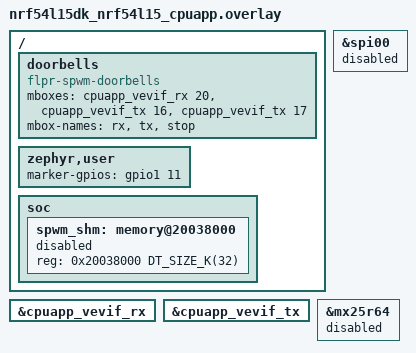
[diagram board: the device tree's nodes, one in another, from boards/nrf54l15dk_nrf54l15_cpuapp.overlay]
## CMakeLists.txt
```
#
# Copyright (c) 2026 Nordic Semiconductor ASA
#
# SPDX-License-Identifier: Apache-2.0
#

cmake_minimum_required(VERSION 3.20.0)

# The FLPR image in remote/ only builds through sysbuild.cmake. An app-only build still links,
# then boots whatever is in the FLPR partition.
if(NOT SYSBUILD)
  message(FATAL_ERROR "flpr_spwm needs sysbuild: west build --sysbuild ...")
endif()

# Reserves FLPR code/data SRAM and makes the app core boot the FLPR image.
list(APPEND SNIPPET nordic-flpr)

find_package(Zephyr REQUIRED HINTS $ENV{ZEPHYR_BASE})
project(flpr_spwm)

target_sources(app PRIVATE src/main.c src/pattern.c src/spwm.c)
target_include_directories(app PRIVATE include)
```

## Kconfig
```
# Copyright (c) 2026 Nordic Semiconductor ASA
#
# SPDX-License-Identifier: Apache-2.0

config FLPR_SPWM_BLE
	bool "Advertise over BLE while the FLPR streams"
	depends on BT
	help
	  Non-connectable advertising at a 20 ms interval, to load the app core
	  and RAM while the bench cases run (B5, O3). overlay-ble.conf sets it.

source "Kconfig.zephyr"
```

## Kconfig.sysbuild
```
# Copyright (c) 2026 Nordic Semiconductor ASA
#
# SPDX-License-Identifier: Apache-2.0

source "share/sysbuild/Kconfig"

config REMOTE_BOARD
	string "FLPR board target"
	default "nrf54l15dk/nrf54l15/cpuflpr" if $(BOARD) = "nrf54l15dk"
	default "nrf54lm20dk/nrf54lm20a/cpuflpr" if "$(BOARD)/$(BOARD_QUALIFIERS)" = "nrf54lm20dk/nrf54lm20a/cpuapp"
```

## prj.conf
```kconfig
CONFIG_MBOX=y
CONFIG_LOG=y
# sinf() in hardware. Load marker: 358 -> 204 us for a 10-step compile at 64 MHz.
CONFIG_FPU=y
```

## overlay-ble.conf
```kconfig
# B5: BLE advertising on the app core while the FLPR streams
CONFIG_BT=y
CONFIG_BT_DEVICE_NAME="flpr_spwm"
CONFIG_FLPR_SPWM_BLE=y
```

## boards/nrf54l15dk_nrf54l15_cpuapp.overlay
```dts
/*
 * Copyright (c) 2026 Nordic Semiconductor ASA
 *
 * SPDX-License-Identifier: Apache-2.0
 */

/* VEVIF doorbells. The app rings FLPR task 16 (START) and 17 (STOP), and the FLPR answers on
 * event 20 (DONE), the only FLPR->app event Zephyr's vevif event-rx accepts on 54L.
 */
/ {
	doorbells {
		compatible = "flpr-spwm-doorbells";
		mboxes = <&cpuapp_vevif_rx 20>, <&cpuapp_vevif_tx 16>, <&cpuapp_vevif_tx 17>;
		mbox-names = "rx", "tx", "stop";
	};
};

/* nordic-flpr only enables the tx side */
&cpuapp_vevif_rx {
	status = "okay";
};

&cpuapp_vevif_tx {
	status = "okay";
};

/* Load marker, high while the app compiles and loads a pattern. P1.11 is only on
 * the expansion-header gpio-map, no board device claims it.
 */
/ {
	zephyr,user {
		marker-gpios = <&gpio1 11 GPIO_ACTIVE_HIGH>;
	};
};

/* P2.01/P2.02 are the only VIO0/VIO1 pins and the DK routes them to the external flash.
 * The FLPR takes them, so the flash has to go. Board Configurator moves them to the P2 header.
 */
&spi00 {
	status = "disabled";
};

&mx25r64 {
	status = "disabled";
};

/* Control block + pattern buffers, top 32 KB of the nordic-flpr region. The FLPR image is
 * linked into the bottom 64 KB (remote overlay). The snippet's reserved node still covers
 * all 96 KB, so the app never links anything here.
 * nordic_vpr_launcher copies all 96 KB from RRAM at boot, so the app fills it after that.
 */
/ {
	soc {
		spwm_shm: memory@20038000 {
			reg = <0x20038000 DT_SIZE_K(32)>;
			status = "reserved";
		};
	};
};
```

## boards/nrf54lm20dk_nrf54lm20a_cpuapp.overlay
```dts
/*
 * Copyright (c) 2026 Nordic Semiconductor ASA
 *
 * SPDX-License-Identifier: Apache-2.0
 */

/* Same doorbells as nRF54L15, see nrf54l15dk_nrf54l15_cpuapp.overlay */
/ {
	doorbells {
		compatible = "flpr-spwm-doorbells";
		mboxes = <&cpuapp_vevif_rx 20>, <&cpuapp_vevif_tx 16>, <&cpuapp_vevif_tx 17>;
		mbox-names = "rx", "tx", "stop";
	};
};

&cpuapp_vevif_rx {
	status = "okay";
};

&cpuapp_vevif_tx {
	status = "okay";
};

/* Load marker, high while the app compiles and loads a pattern. P1.03 is only on
 * the expansion-header gpio-map, no board device claims it.
 */
/ {
	zephyr,user {
		marker-gpios = <&gpio1 3 GPIO_ACTIVE_HIGH>;
	};
};

/* P2.01/P2.02 are the only VIO0/VIO1 pins and the DK routes them to the external flash.
 * The FLPR takes them, so the flash has to go. Board Configurator moves them to the P2 header.
 */
&spi00 {
	status = "disabled";
};

&mx25r64 {
	status = "disabled";
};

/* Control block + pattern buffers, top 32 KB of the nordic-flpr region. The FLPR image is
 * linked into the bottom 64 KB (remote overlay). The snippet's reserved node still covers
 * all 96 KB, so the app never links anything here.
 * nordic_vpr_launcher copies all 96 KB from RRAM at boot, so the app fills it after that.
 */
/ {
	soc {
		spwm_shm: memory@20077c00 {
			reg = <0x20077c00 DT_SIZE_K(32)>;
			status = "reserved";
		};
	};
};
```

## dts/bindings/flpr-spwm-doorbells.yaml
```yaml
# Copyright (c) 2026 Nordic Semiconductor ASA
#
# SPDX-License-Identifier: Apache-2.0

description: VEVIF doorbells between the app core and the FLPR

compatible: "flpr-spwm-doorbells"

include: base.yaml

properties:
  mboxes:
    required: true

  mbox-names:
    required: true
```

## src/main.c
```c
/*
 * Copyright (c) 2026 Nordic Semiconductor ASA
 *
 * SPDX-License-Identifier: Apache-2.0
 */

/** @file
 *  @brief App core side of flpr_spwm.
 *
 *  Bench sequence, repeated: compile a pattern with the load marker high, START it, wait
 *  for DONE, log the result. One case per bench milestone, see cases[].
 */

#include <zephyr/kernel.h>
#include <zephyr/logging/log.h>
#include <zephyr/bluetooth/bluetooth.h>

#include "pattern.h"
#include "spwm.h"
#include "spwm_ipc.h"

LOG_MODULE_REGISTER(flpr_spwm, LOG_LEVEL_INF);

#define GAP_MS 200
#define MAX_STEPS 4096
#define BUF_OFF SPWM_SHM_BUF_OFF
#define REF_HZ 200000
#define RATIO 10 /* carrier = 10 * ref, 2 MHz at 200 kHz */

/* loop_cnt that plays about 20 ms, whatever the buffer length */
#define LOOPS_20MS UINT32_MAX

enum shape {
	SHAPE_ALT, /* A, B, A, B at the minimum dead time, worst case for A/B changes */
	SHAPE_SINE,
	SHAPE_RETUNE,   /* sine at f_ref, then retune_hz from a second buffer, then STOP */
	SHAPE_MINPULSE, /* A only, on_ticks 1..8 in 32-tick periods */
};

struct bench_case {
	const char *name;
	enum shape shape;
	uint16_t cnttop;
	uint16_t dead_ticks;
	uint32_t loop_cnt; /* 0: run until spwm_stop() after stop_after_us */
	uint32_t stop_after_us;
	uint32_t f_ref;     /* 0: REF_HZ */
	uint32_t max_words; /* planner buffer cap, 0: one ref cycle */
	uint32_t retune_hz;
};

static const struct bench_case cases[] = {
	{"b2_alt_64M", SHAPE_ALT, 1, 2, 1000},
	{"b3_sine_64M", SHAPE_SINE, 1, 2, 2000},
	{"b3_sine_128M", SHAPE_SINE, 0, 4, 2000},
	{"b4_n100_64M", SHAPE_SINE, 1, 2, 100},
	{"b4_stop_64M", SHAPE_SINE, 1, 2, 0, 2000},
	/* STOP right after START, before the FLPR picks it up: must still stop after one pass */
	{"b4_stop_early_64M", SHAPE_SINE, 1, 2, 0, 0},
	{"b6_retune_64M", SHAPE_RETUNE, 1, 2, 0, 1000, 0, 0, 188235},
	/* Limits at 128 MHz: 1-tick dead time, pulse floor, fine frequency steps */
	{"b2_alt_128M_d1", SHAPE_ALT, 0, 1, 2000},
	{"b8_minpulse_128M", SHAPE_MINPULSE, 0, 4, 1000},
	{"b7_f200000", SHAPE_SINE, 0, 1, LOOPS_20MS, 0, 200000, SPWM_SHM_BUF_MAX_WORDS},
	{"b7_f187654", SHAPE_SINE, 0, 1, LOOPS_20MS, 0, 187654, SPWM_SHM_BUF_MAX_WORDS},
	{"b7_f187655", SHAPE_SINE, 0, 1, LOOPS_20MS, 0, 187655, SPWM_SHM_BUF_MAX_WORDS},
	{"b7_f187664", SHAPE_SINE, 0, 1, LOOPS_20MS, 0, 187664, SPWM_SHM_BUF_MAX_WORDS},
};

static struct spwm_step steps[MAX_STEPS];
static struct spwm_sine_plan plan;

#if defined(CONFIG_FLPR_SPWM_BLE)
static const struct bt_data ad[] = {
	BT_DATA_BYTES(BT_DATA_FLAGS, BT_LE_AD_NO_BREDR),
	BT_DATA(BT_DATA_NAME_COMPLETE, CONFIG_BT_DEVICE_NAME, sizeof(CONFIG_BT_DEVICE_NAME) - 1),
};

/* 20 ms, the shortest advertising interval (BT Core v5.x, Vol 6, Part B, 4.4.2.2.1) */
#define ADV_INT_20MS 0x20

static int ble_start(void)
{
	const struct bt_le_adv_param param =
		BT_LE_ADV_PARAM_INIT(BT_LE_ADV_OPT_USE_IDENTITY, ADV_INT_20MS, ADV_INT_20MS, NULL);
	int err;

	err = bt_enable(NULL);
	if (err) {
		LOG_ERR("bt_enable failed (err %d)", err);
		return err;
	}

	err = bt_le_adv_start(&param, ad, ARRAY_SIZE(ad), NULL, 0);
	if (err) {
		LOG_ERR("bt_le_adv_start failed (err %d)", err);
		return err;
	}

	LOG_INF("advertising as %s every 20 ms", CONFIG_BT_DEVICE_NAME);

	return 0;
}
#else
static int ble_start(void)
{
	return -ENOTSUP;
}
#endif /* CONFIG_FLPR_SPWM_BLE */

static uint32_t tick_hz_of(const struct bench_case *c)
{
	return 128000000U / (c->cnttop + 1U);
}

/* Plans and compiles a sine into spwm_shm at off. max_words 0 = one ref cycle, as before. */
static int build_sine(const struct bench_case *c, uint32_t f_ref, uint32_t max_words,
		      uint32_t off)
{
	uint32_t room = SPWM_SHM_BUF_MAX_WORDS - (off - BUF_OFF) / sizeof(uint32_t);
	uint32_t tick_hz = tick_hz_of(c);
	uint32_t max_ticks;
	int n;
	int err;

	if (max_words == 0) {
		/* One ref cycle, rounded to whole words */
		max_ticks = ROUND_UP(tick_hz / f_ref, SPWM_TICKS_PER_WORD);
	} else {
		max_ticks = MIN(max_words, room) * SPWM_TICKS_PER_WORD;
	}

	err = spwm_sine_plan(f_ref, RATIO, tick_hz, max_ticks, MAX_STEPS, &plan);
	if (err) {
		return err;
	}

	n = spwm_sine_build(&plan, 100, c->dead_ticks, steps, MAX_STEPS);
	if (n < 0) {
		return n;
	}

	return spwm_compile(steps, n, c->dead_ticks, (uint32_t *)SPWM_BUF(off), room);
}

static int build(const struct bench_case *c)
{
	size_t n;

	switch (c->shape) {
	case SHAPE_ALT:
		/* period 16, pulse fills it but for dead_ticks each side */
		n = 4;
		for (size_t k = 0; k < n; k++) {
			steps[k] = (struct spwm_step){
				.leg = (k & 1) ? SPWM_LEG_B : SPWM_LEG_A,
				.dead_ticks = c->dead_ticks,
				.on_ticks = 16 - 2 * c->dead_ticks,
				.period_ticks = 16,
			};
		}
		break;
	case SHAPE_MINPULSE:
		n = 8;
		for (size_t k = 0; k < n; k++) {
			steps[k] = (struct spwm_step){
				.leg = SPWM_LEG_A,
				.dead_ticks = c->dead_ticks,
				.on_ticks = k + 1,
				.period_ticks = 32,
			};
		}
		break;
	default:
		return build_sine(c, c->f_ref ? c->f_ref : REF_HZ, c->max_words, BUF_OFF);
	}

	return spwm_compile(steps, n, c->dead_ticks, (uint32_t *)SPWM_BUF(BUF_OFF),
			    SPWM_SHM_BUF_MAX_WORDS);
}

static int run_case(const struct bench_case *c)
{
	uint32_t t_start, t_done;
	uint32_t retune_off = 0;
	int retune_words = 0;
	int words;
	int err;

	spwm_marker(true);
	words = build(c);
	if (c->shape == SHAPE_RETUNE && words > 0) {
		retune_off = BUF_OFF + words * sizeof(uint32_t);
		retune_words = build_sine(c, c->retune_hz, 85, retune_off);
	}
	spwm_marker(false);
	if (retune_words < 0) {
		LOG_ERR("%s: retune compile failed (err %d)", c->name, retune_words);
		return retune_words;
	}
	if (words < 0) {
		LOG_ERR("%s: compile failed (err %d)", c->name, words);
		return words;
	}

	uint32_t loop_cnt = c->loop_cnt;

	if (loop_cnt == LOOPS_20MS) {
		/* words * 16 ticks per pass */
		loop_cnt = MAX(1U, (uint32_t)((uint64_t)tick_hz_of(c) / 50U /
					      ((uint64_t)words * SPWM_TICKS_PER_WORD)));
	}

	if (c->shape == SHAPE_SINE && c->max_words) {
		LOG_INF("%s: plan M %u L %u ticks, f %u.%03u Hz", c->name, plan.cycles, plan.ticks,
			(uint32_t)(plan.f_mhz / 1000U), (uint32_t)(plan.f_mhz % 1000U));
	}

	t_start = k_cycle_get_32();
	err = spwm_start(BUF_OFF, words, c->cnttop, loop_cnt);
	if (err) {
		LOG_ERR("%s: spwm_start failed (err %d)", c->name, err);
		return err;
	}

	if (c->shape == SHAPE_RETUNE) {
		k_busy_wait(c->stop_after_us);
		err = spwm_retune(retune_off, retune_words);
		if (err) {
			LOG_ERR("%s: spwm_retune failed (err %d)", c->name, err);
			return err;
		}
	}

	if (loop_cnt == 0) {
		k_busy_wait(c->stop_after_us);
		err = spwm_stop();
		if (err) {
			LOG_ERR("%s: spwm_stop failed (err %d)", c->name, err);
			return err;
		}
	}

	err = spwm_wait_done(K_SECONDS(1), &t_done);
	if (err) {
		LOG_ERR("%s: no DONE, state %u", c->name, SPWM_CTRL->state);
		return err;
	}

	LOG_INF("%s: %d words, cnttop %u, loop_cnt %u, loops_done %u, state %u, "
		"START->DONE %u us",
		c->name, words, c->cnttop, loop_cnt, SPWM_CTRL->loops_done, SPWM_CTRL->state,
		k_cyc_to_us_floor32(t_done - t_start));

	return 0;
}

int main(void)
{
	int err;

	err = spwm_init();
	if (err) {
		return err;
	}

	if (IS_ENABLED(CONFIG_FLPR_SPWM_BLE)) {
		err = ble_start();
		if (err) {
			return err;
		}
	}

	LOG_INF("flpr_spwm on %s, spwm_shm 0x%08x, %u buffer words", CONFIG_BOARD_TARGET,
		SPWM_SHM_ADDR, SPWM_SHM_BUF_MAX_WORDS);

	while (1) {
		for (size_t i = 0; i < ARRAY_SIZE(cases); i++) {
			(void)run_case(&cases[i]);
			k_msleep(GAP_MS);
		}
	}

	return 0;
}
```

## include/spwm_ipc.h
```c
/*
 * Copyright (c) 2026 Nordic Semiconductor ASA
 *
 * SPDX-License-Identifier: Apache-2.0
 */

/** @file
 *  @brief Control block shared by the app core and the FLPR.
 *
 *  Lives at the start of the spwm_shm DT region, which both images carve out of the
 *  top 32 KB of the nordic-flpr SRAM. Pattern buffers follow it in the same region.
 *  All offsets are bytes from the region base, so neither side needs the other's pointers.
 */

#ifndef SPWM_IPC_H_
#define SPWM_IPC_H_

#include <stdint.h>
#include <zephyr/devicetree.h>

#define SPWM_IPC_VERSION 2

#define SPWM_SHM_ADDR DT_REG_ADDR(DT_NODELABEL(spwm_shm))
#define SPWM_SHM_SIZE DT_REG_SIZE(DT_NODELABEL(spwm_shm))

/* Pattern buffers start here, 64 B keeps the control block on its own */
#define SPWM_SHM_BUF_OFF 64U
#define SPWM_SHM_BUF_MAX_WORDS ((SPWM_SHM_SIZE - SPWM_SHM_BUF_OFF) / sizeof(uint32_t))

/* One 32-bit OUTB word holds 16 two-bit frames (FRAMEWIDTH = 2, SHIFTCNTB = 15) */
#define SPWM_TICKS_PER_WORD 16U

enum spwm_state {
	SPWM_STATE_IDLE = 0,
	SPWM_STATE_ARMED,
	SPWM_STATE_RUNNING,
	SPWM_STATE_DONE,
	SPWM_STATE_ERROR,
};

enum spwm_err {
	SPWM_ERR_NONE = 0,
	SPWM_ERR_VERSION,
	SPWM_ERR_BUF,
};

struct spwm_ctrl {
	uint32_t version;        /* app: SPWM_IPC_VERSION, FLPR checks it at START */
	uint32_t state;          /* FLPR: enum spwm_state */
	uint32_t err;            /* FLPR: enum spwm_err when state is ERROR */
	uint32_t buf_off;        /* app: buffer to play */
	uint32_t buf_words;      /* app */
	uint32_t next_buf_off;   /* app: retune, taken at the next wrap with pending. 0 = none */
	uint32_t next_buf_words; /* app */
	uint32_t loop_cnt;       /* app: buffer plays per START. 0 = until STOP */
	uint32_t cnttop;         /* app: VTIM CNT0 top, tick = 128 MHz / (cnttop + 1) (O2) */
	uint32_t stop_req;       /* app: taken at the next wrap with pending */
	uint32_t loops_done;     /* FLPR: written at the end, and at a wrap that sees pending */
	uint32_t pending;        /* app: set last, after stop_req or next_buf_*. FLPR clears it */
};

BUILD_ASSERT(sizeof(struct spwm_ctrl) <= SPWM_SHM_BUF_OFF, "control block overlaps buffers");

#define SPWM_CTRL ((volatile struct spwm_ctrl *)SPWM_SHM_ADDR)
#define SPWM_BUF(off) ((volatile uint32_t *)(SPWM_SHM_ADDR + (off)))

#endif /* SPWM_IPC_H_ */
```

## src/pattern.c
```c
/*
 * Copyright (c) 2026 Nordic Semiconductor ASA
 *
 * SPDX-License-Identifier: Apache-2.0
 */

#include <errno.h>
#include <math.h>
#include <string.h>

#include "pattern.h"

#define TICKS_PER_WORD 16 /* FRAMEWIDTH 2 in a 32-bit OUTB word */
#define FRAME_A 0x1U      /* VIO0 */
#define FRAME_B 0x2U      /* VIO1 */

#define PI_F 3.14159265f

static uint32_t frame_get(const uint32_t *buf, size_t tick)
{
	return (buf[tick / TICKS_PER_WORD] >> (2 * (tick % TICKS_PER_WORD))) & 0x3U;
}

int spwm_sine_plan(uint32_t f_ref, uint16_t carrier_ratio, uint32_t tick_hz, uint32_t max_ticks,
		   size_t max_steps, struct spwm_sine_plan *plan)
{
	uint64_t best_err = UINT64_MAX;
	uint32_t best_l = 0;
	uint32_t best_m = 0;

	if (f_ref == 0 || carrier_ratio == 0 || tick_hz == 0) {
		return -EINVAL;
	}

	for (uint32_t l = TICKS_PER_WORD; l <= max_ticks; l += TICKS_PER_WORD) {
		uint32_t m = (uint32_t)(((uint64_t)f_ref * l + tick_hz / 2) / tick_hz);

		if (m == 0 || (uint64_t)m * carrier_ratio > max_steps) {
			continue;
		}

		/* |tick_hz * M / L - f_ref| * L, compared across L by cross-multiplying */
		uint64_t a = (uint64_t)tick_hz * m;
		uint64_t b = (uint64_t)f_ref * l;
		uint64_t err = a > b ? a - b : b - a;

		if (best_l == 0 || err * best_l < best_err * l) {
			best_err = err;
			best_l = l;
			best_m = m;
			if (err == 0) {
				break;
			}
		}
	}

	if (best_l == 0) {
		return -EINVAL;
	}

	plan->tick_hz = tick_hz;
	plan->carrier_ratio = carrier_ratio;
	plan->cycles = best_m;
	plan->ticks = best_l;
	plan->f_mhz = ((uint64_t)tick_hz * 1000U * best_m + best_l / 2) / best_l;

	return 0;
}

int spwm_sine_build(const struct spwm_sine_plan *plan, uint8_t depth_pct, uint16_t dead_ticks,
		    struct spwm_step *steps, size_t max_steps)
{
	uint32_t n = plan->cycles * plan->carrier_ratio;
	uint32_t l = plan->ticks;

	if (depth_pct > 100) {
		return -EINVAL;
	}
	if (n > max_steps) {
		return -ENOMEM;
	}

	for (uint32_t k = 0; k < n; k++) {
		/* Carrier k spans [s, e), edges on the nearest tick below k * L / N */
		uint32_t s = (uint32_t)((uint64_t)k * l / n);
		uint32_t e = (uint32_t)((uint64_t)(k + 1) * l / n);
		uint32_t period = e - s;

		if (period > UINT16_MAX || period <= 2U * dead_ticks) {
			return -EINVAL;
		}

		/* Phase at the carrier center (s + e) / 2, reduced mod 2L in integers first */
		uint64_t num = ((uint64_t)plan->cycles * (s + e)) % (2ULL * l);
		float v = sinf(2.0f * PI_F * (float)num / (float)(2U * l));
		uint32_t on = (uint32_t)lroundf(fabsf(v) * depth_pct * (period - 2U * dead_ticks) /
						100.0f);

		steps[k].period_ticks = period;
		steps[k].dead_ticks = dead_ticks;
		steps[k].on_ticks = on;
		steps[k].leg = (on == 0) ? SPWM_LEG_NONE : (v > 0.0f ? SPWM_LEG_A : SPWM_LEG_B);
	}

	return (int)n;
}

int spwm_validate(const uint32_t *buf, size_t words, uint16_t min_dead_ticks)
{
	size_t ticks = words * TICKS_PER_WORD;
	uint32_t last = 0;
	uint32_t low_run = 0;

	/* Two passes, so the A/B change across the wrap is checked with real history */
	for (size_t i = 0; i < 2 * ticks; i++) {
		uint32_t f = frame_get(buf, i % ticks);

		if (f == (FRAME_A | FRAME_B)) {
			return -EINVAL;
		}

		if (f == 0) {
			low_run++;
			continue;
		}

		if (last != 0 && last != f && low_run < min_dead_ticks) {
			return -EINVAL;
		}

		last = f;
		low_run = 0;
	}

	return 0;
}

int spwm_compile(const struct spwm_step *steps, size_t n, uint16_t min_dead_ticks,
		 uint32_t *buf, size_t max_words)
{
	size_t ticks = 0;

	for (size_t k = 0; k < n; k++) {
		const struct spwm_step *s = &steps[k];

		if (s->leg > SPWM_LEG_B || s->period_ticks == 0 || s->dead_ticks < min_dead_ticks ||
		    2U * s->dead_ticks + s->on_ticks > s->period_ticks) {
			return -EINVAL;
		}
		ticks += s->period_ticks;
	}

	size_t words = (ticks + TICKS_PER_WORD - 1) / TICKS_PER_WORD;

	if (words == 0 || words > max_words) {
		return -ENOMEM;
	}

	memset(buf, 0, words * sizeof(uint32_t));

	size_t t = 0;

	for (size_t k = 0; k < n; k++) {
		const struct spwm_step *s = &steps[k];
		uint32_t frame = (s->leg == SPWM_LEG_A) ? FRAME_A : FRAME_B;
		/* Centered pulse, odd leftover tick goes after it */
		size_t start = t + (s->period_ticks - s->on_ticks) / 2;

		if (s->leg != SPWM_LEG_NONE) {
			for (size_t i = start; i < start + s->on_ticks; i++) {
				buf[i / TICKS_PER_WORD] |= frame << (2 * (i % TICKS_PER_WORD));
			}
		}
		t += s->period_ticks;
	}

	if (spwm_validate(buf, words, min_dead_ticks)) {
		return -EINVAL;
	}

	return (int)words;
}
```

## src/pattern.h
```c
/*
 * Copyright (c) 2026 Nordic Semiconductor ASA
 *
 * SPDX-License-Identifier: Apache-2.0
 */

/** @file
 *  @brief Bit-pattern compiler for the FLPR streamer.
 *
 *  A step is one carrier period, the analogue of one PWM SEQ value. Steps compile to
 *  2-bit frames, 16 per 32-bit word, LSB first, frame bits [1:0] = {leg B, leg A}.
 */

#ifndef SPWM_PATTERN_H_
#define SPWM_PATTERN_H_

#include <stddef.h>
#include <stdint.h>

enum spwm_leg {
	SPWM_LEG_NONE = 0,
	SPWM_LEG_A,
	SPWM_LEG_B,
};

struct spwm_step {
	uint8_t leg;           /* enum spwm_leg */
	uint16_t dead_ticks;   /* minimum low time before and after the pulse */
	uint16_t on_ticks;     /* pulse width, centered in the period */
	uint16_t period_ticks;
};

/** @brief Buffer layout for a sine at the closest reachable f_ref. */
struct spwm_sine_plan {
	uint32_t tick_hz;
	uint16_t carrier_ratio; /* carrier periods per ref period */
	uint32_t cycles;        /* M, ref cycles in one buffer */
	uint32_t ticks;         /* L, buffer length, a multiple of 16 */
	uint64_t f_mhz;         /* reached f_ref in mHz, tick_hz * M / L */
};

/**
 * @brief Pick the buffer that gets closest to f_ref.
 *
 * f_ref = tick_hz * M / L, L a multiple of 16 ticks. Searches every L up to max_ticks, so a
 * longer buffer gives a finer f_ref and a slower retune (one pass is L ticks). Carrier edges
 * land on the nearest tick, so carrier periods differ by at most one tick inside a buffer.
 *
 * @param f_ref         target, Hz
 * @param carrier_ratio carrier = carrier_ratio * f_ref
 * @param tick_hz       128 MHz / (cnttop + 1)
 * @param max_ticks     longest buffer allowed
 * @param max_steps     step array size, M * carrier_ratio must fit
 * @param plan          output
 *
 * @retval -EINVAL if nothing fits
 */
int spwm_sine_plan(uint32_t f_ref, uint16_t carrier_ratio, uint32_t tick_hz, uint32_t max_ticks,
		   size_t max_steps, struct spwm_sine_plan *plan);

/**
 * @brief Fill steps for a plan, natural-sampled at each carrier's center.
 *
 * Sign picks the leg, |sin| * depth scales the pulse between 0 and period - 2 * dead.
 *
 * @return steps written (M * carrier_ratio), or -EINVAL if a carrier can't hold the dead
 *         time, -ENOMEM if max_steps is too small
 */
int spwm_sine_build(const struct spwm_sine_plan *plan, uint8_t depth_pct, uint16_t dead_ticks,
		    struct spwm_step *steps, size_t max_steps);

/**
 * @brief Pack steps into OUTB words, then validate the words.
 *
 * Pads with low frames to a 16-tick multiple.
 *
 * @param steps          input
 * @param n              step count
 * @param min_dead_ticks dead time every step and every A/B change must honour
 * @param buf            output words
 * @param max_words      buf size
 *
 * @return words written, or -EINVAL on a bad step or failed validation, -ENOMEM if it
 *         doesn't fit
 */
int spwm_compile(const struct spwm_step *steps, size_t n, uint16_t min_dead_ticks,
		 uint32_t *buf, size_t max_words);

/**
 * @brief Check packed words as the FLPR will play them, looping.
 *
 * @retval 0 if no frame has A and B high, and every A->B or B->A change has at least
 *         min_dead_ticks low frames between, including across the buffer wrap
 * @retval -EINVAL otherwise
 */
int spwm_validate(const uint32_t *buf, size_t words, uint16_t min_dead_ticks);

#endif /* SPWM_PATTERN_H_ */
```

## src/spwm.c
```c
/*
 * Copyright (c) 2026 Nordic Semiconductor ASA
 *
 * SPDX-License-Identifier: Apache-2.0
 */

#include <zephyr/kernel.h>
#include <zephyr/drivers/mbox.h>
#include <zephyr/drivers/gpio.h>
#include <zephyr/drivers/clock_control/nrf_clock_control.h>
#include <zephyr/logging/log.h>
#include <soc.h>
#include <hal/nrf_gpio.h>

#include "spwm.h"
#include "spwm_ipc.h"

LOG_MODULE_REGISTER(spwm, LOG_LEVEL_INF);

#define MARKER_PIN NRF_DT_GPIOS_TO_PSEL(DT_PATH(zephyr_user), marker_gpios)

static const struct gpio_dt_spec marker = GPIO_DT_SPEC_GET(DT_PATH(zephyr_user), marker_gpios);

static const struct mbox_dt_spec rx = MBOX_DT_SPEC_GET(DT_PATH(doorbells), rx);
static const struct mbox_dt_spec tx = MBOX_DT_SPEC_GET(DT_PATH(doorbells), tx);
static const struct mbox_dt_spec stop = MBOX_DT_SPEC_GET(DT_PATH(doorbells), stop);

static K_SEM_DEFINE(done_sem, 0, 1);
static volatile uint32_t done_cyc_isr;

void spwm_marker(bool on)
{
	/* Straight to the port, gpio_pin_set_dt() adds a few hundred ns of API on the marker */
	if (on) {
		nrf_gpio_pin_set(MARKER_PIN);
	} else {
		nrf_gpio_pin_clear(MARKER_PIN);
	}
}

/* VPR00 IRQ 76. The marker pulse puts DONE on the same Logic channel as the load marker. */
static void done_cb(const struct device *dev, mbox_channel_id_t channel_id, void *user_data,
		    struct mbox_msg *data)
{
	nrf_gpio_pin_set(MARKER_PIN);
	nrf_gpio_pin_clear(MARKER_PIN);
	/* After the pulse: a GRTC read took 0.9-30 us here on the bench */
	done_cyc_isr = k_cycle_get_32();
	k_sem_give(&done_sem);
}

static int hfxo_start(void)
{
	struct onoff_manager *mgr = z_nrf_clock_control_get_onoff(CLOCK_CONTROL_NRF_SUBSYS_HF);
	struct onoff_client cli;
	int res;
	int err;

	sys_notify_init_spinwait(&cli.notify);
	err = onoff_request(mgr, &cli);
	if (err < 0) {
		return err;
	}

	do {
		err = sys_notify_fetch_result(&cli.notify, &res);
	} while (err == -EAGAIN);

	return err ? err : res;
}

int spwm_init(void)
{
	int err;

	/* HFINT alone put the tick +587 to +1275 ppm off, HFXO +8 ppm (B1) */
	err = hfxo_start();
	if (err) {
		LOG_ERR("HFXO start failed (err %d)", err);
		return err;
	}

	err = gpio_pin_configure_dt(&marker, GPIO_OUTPUT_INACTIVE);
	if (err) {
		LOG_ERR("marker configure failed (err %d)", err);
		return err;
	}

	err = mbox_register_callback_dt(&rx, done_cb, NULL);
	if (err) {
		LOG_ERR("mbox_register_callback_dt failed (err %d)", err);
		return err;
	}

	err = mbox_set_enabled_dt(&rx, true);
	if (err) {
		LOG_ERR("mbox_set_enabled_dt failed (err %d)", err);
		return err;
	}

	/* nordic_vpr_launcher has copied the FLPR image by now, so this sticks */
	SPWM_CTRL->state = SPWM_STATE_IDLE;
	SPWM_CTRL->err = SPWM_ERR_NONE;
	SPWM_CTRL->next_buf_off = 0;
	SPWM_CTRL->stop_req = 0;
	SPWM_CTRL->version = SPWM_IPC_VERSION;

	return 0;
}

int spwm_start(uint32_t buf_off, uint32_t words, uint16_t cnttop, uint32_t loop_cnt)
{
	volatile struct spwm_ctrl *ctrl = SPWM_CTRL;

	if (ctrl->state == SPWM_STATE_RUNNING) {
		return -EBUSY;
	}

	k_sem_reset(&done_sem);

	ctrl->buf_off = buf_off;
	ctrl->buf_words = words;
	ctrl->next_buf_off = 0;
	ctrl->loop_cnt = loop_cnt;
	ctrl->cnttop = cnttop;
	ctrl->stop_req = 0;
	ctrl->pending = 0;
	ctrl->state = SPWM_STATE_ARMED;

	return mbox_send_dt(&tx, NULL);
}

int spwm_retune(uint32_t buf_off, uint32_t words)
{
	volatile struct spwm_ctrl *ctrl = SPWM_CTRL;

	if (ctrl->pending) {
		return -EBUSY;
	}

	ctrl->next_buf_off = buf_off;
	ctrl->next_buf_words = words;
	ctrl->pending = 1;

	return 0;
}

int spwm_stop(void)
{
	SPWM_CTRL->stop_req = 1;
	SPWM_CTRL->pending = 1;

	return mbox_send_dt(&stop, NULL);
}

int spwm_wait_done(k_timeout_t timeout, uint32_t *done_cyc)
{
	int err = k_sem_take(&done_sem, timeout);

	if (!err && done_cyc) {
		*done_cyc = done_cyc_isr;
	}

	return err;
}
```

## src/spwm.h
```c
/*
 * Copyright (c) 2026 Nordic Semiconductor ASA
 *
 * SPDX-License-Identifier: Apache-2.0
 */

/** @file
 *  @brief App core control of the FLPR streamer: START, STOP, DONE.
 */

#ifndef SPWM_H_
#define SPWM_H_

#include <stdint.h>
#include <zephyr/kernel.h>

/** @brief Start HFXO, set up the doorbells and the marker pin, reset the control block. */
int spwm_init(void);

/** @brief Load marker, P1.11 on nRF54L15DK. High while compiling and loading. */
void spwm_marker(bool on);

/**
 * @brief Write the control block and ring START.
 *
 * @param buf_off  byte offset of the words in spwm_shm
 * @param words    buffer length
 * @param cnttop   tick = 128 MHz / (cnttop + 1)
 * @param loop_cnt buffer plays, 0 = until spwm_stop()
 *
 * @retval -EBUSY if the FLPR is running
 */
int spwm_start(uint32_t buf_off, uint32_t words, uint16_t cnttop, uint32_t loop_cnt);

/**
 * @brief Queue another buffer. The FLPR switches to it at a wrap, one pass after it sees it.
 *
 * @retval -EBUSY if the previous retune or stop hasn't been taken yet
 */
int spwm_retune(uint32_t buf_off, uint32_t words);

/** @brief Set stop_req and ring STOP. The FLPR takes it at the next buffer wrap. */
int spwm_stop(void);

/**
 * @brief Wait for DONE.
 *
 * @param timeout    how long to wait
 * @param done_cyc   k_cycle_get_32() in the DONE ISR
 *
 * @retval -EAGAIN on timeout
 */
int spwm_wait_done(k_timeout_t timeout, uint32_t *done_cyc);

#endif /* SPWM_H_ */
```
